VERSION ""

NS_ :

BS_:

BU_: XXX

BO_ 134 Steering: 8 XXX
 SG_ Steering_Angle : 16|16@1+ (1,0) [0|65535] "" XXX

BO_ 162 NEW_MSG_2: 8 XXX

BO_ 128 NEW_MSG_3: 8 XXX

BO_ 143 Experimenting1: 8 XXX
 SG_ DontKnow_but_something : 32|16@1+ (0.5,0) [0|65535] "" XXX

BO_ 256 NEW_MSG_5: 8 XXX
 SG_ NEW_SIGNAL_2 : 40|16@1+ (1,0) [0|65535] "" XXX
 SG_ NEW_SIGNAL_1 : 16|16@1+ (1,0) [0|65535] "" XXX

BO_ 161 NEW_MSG_6: 8 XXX

BO_ 262 Brake: 8 XXX
 SG_ Brake_Switch : 61|1@0+ (1,0) [0|1] "on-off" XXX
 SG_ Brake_Pedal_Pressure : 16|16@1+ (1,0) [0|65535] "" XXX

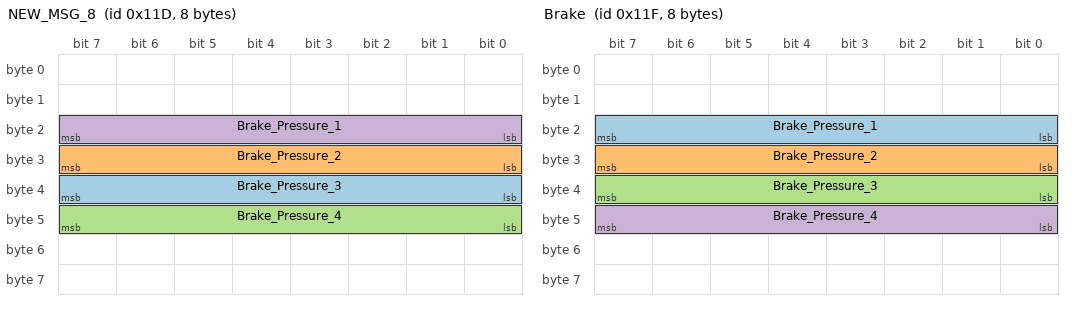
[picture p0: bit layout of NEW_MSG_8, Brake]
BO_ 285 NEW_MSG_8: 8 XXX
 SG_ Brake_Pressure_3 : 32|8@1+ (1,0) [0|255] "" XXX
 SG_ Brake_Pressure_2 : 24|8@1+ (1,0) [0|255] "" XXX
 SG_ Brake_Pressure_4 : 40|8@1+ (1,0) [0|255] "" XXX
 SG_ Brake_Pressure_1 : 16|8@1+ (1,0) [0|255] "" XXX

BO_ 286 NEW_MSG_10: 8 XXX

BO_ 278 NEW_MSG_11: 8 XXX
 SG_ NEW_SIGNAL_1 : 7|16@0+ (1,0) [0|65535] "" XXX

BO_ 276 NEW_MSG_12: 8 XXX
 SG_ NEW_SIGNAL_2 : 24|8@1+ (1,0) [0|255] "" XXX

BO_ 260 NEW_MSG_13: 8 XXX
 SG_ NEW_SIGNAL_1 : 3|4@1+ (1,0) [0|15] "" XXX

BO_ 257 NEW_MSG_14: 8 XXX
 SG_ NEW_SIGNAL_1 : 47|16@0+ (1,0) [0|65535] "" XXX

BO_ 159 NEW_MSG_15: 8 XXX

BO_ 287 Brake: 8 XXX
 SG_ Brake_Pressure_1 : 16|8@1+ (1,0) [0|255] "" XXX
 SG_ Brake_Pressure_2 : 24|8@1+ (1,0) [0|255] "" XXX
 SG_ Brake_Pressure_3 : 32|8@1+ (1,0) [0|255] "" XXX
 SG_ Brake_Pressure_4 : 40|8@1+ (1,0) [0|255] "" XXX

BO_ 259 Speed: 8 XXX
 SG_ Wheel_Speed_1 : 32|8@1+ (1,0) [0|255] "" XXX
 SG_ Wheel_Speed_2 : 56|8@1+ (1,0) [0|255] "" XXX

BO_ 129 NEW_MSG_9: 8 XXX
 SG_ NEW_SIGNAL_1 : 39|8@0+ (1,0) [0|255] "" XXX

BO_ 261 Throttle: 8 XXX
 SG_ Throttle_Pedal_Pst : 48|8@1+ (1,0) [0|255] "" XXX
